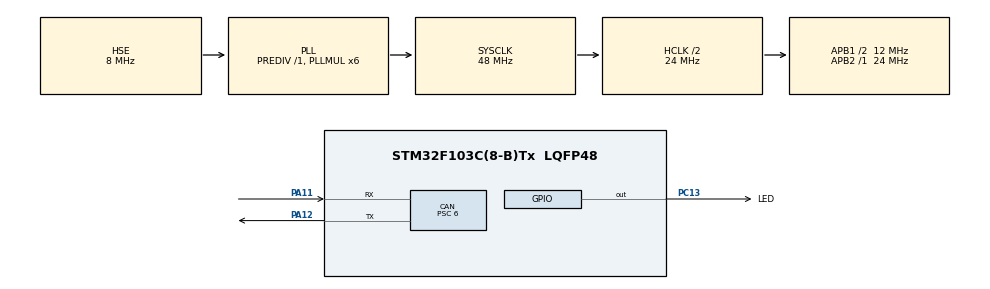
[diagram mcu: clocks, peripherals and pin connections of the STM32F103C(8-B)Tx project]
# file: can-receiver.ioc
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CAN.BS1=CAN_BS1_5TQ
CAN.BS2=CAN_BS2_2TQ
CAN.CalculateTimeBit=4000
CAN.CalculateTimeQuantum=500.0
CAN.NART=DISABLE
CAN.Prescaler=6
Mcu.Family=STM32F1
Mcu.Name=STM32F103C(8-B)Tx
Mcu.Package=LQFP48
NVIC.PriorityGroup=NVIC_PRIORITYGROUP_4
NVIC.USB_LP_CAN1_RX0_IRQn=true\:0\:0\:false\:true\:true\:1\:true\:true
PA11.Mode=Master
PA11.Signal=CAN_RX
PA12.Mode=Master
PA12.Signal=CAN_TX
PA13.Mode=Serial_Wire
PA13.Signal=SYS_JTMS-SWDIO
PA14.Mode=Serial_Wire
PA14.Signal=SYS_JTCK-SWCLK
PC13-TAMPER-RTC.GPIO_Label=LED
PC13-TAMPER-RTC.Signal=GPIO_Output
PD0-OSC_IN.Mode=HSE-External-Oscillator
PD0-OSC_IN.Signal=RCC_OSC_IN
PD1-OSC_OUT.Mode=HSE-External-Oscillator
PD1-OSC_OUT.Signal=RCC_OSC_OUT
ProjectManager.HeapSize=0x200
ProjectManager.StackSize=0x400
ProjectManager.TargetToolchain=STM32CubeIDE
RCC.AHBCLKDivider=RCC_SYSCLK_DIV2
RCC.AHBFreq_Value=24000000
RCC.APB1CLKDivider=RCC_HCLK_DIV2
RCC.APB1Freq_Value=12000000
RCC.APB1TimFreq_Value=24000000
RCC.APB2Freq_Value=24000000
RCC.APB2TimFreq_Value=24000000
RCC.HCLKFreq_Value=24000000
RCC.PLLMUL=RCC_PLL_MUL6
RCC.PLLSourceVirtual=RCC_PLLSOURCE_HSE
RCC.SYSCLKFreq_VALUE=48000000
RCC.SYSCLKSource=RCC_SYSCLKSOURCE_PLLCLK
RCC.USBFreq_Value=48000000
board=custom

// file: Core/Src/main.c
/* USER CODE BEGIN Header */
/**
 ******************************************************************************
 * @file           : main.c
 * @brief          : Main program body
 ******************************************************************************
 * @attention
 *
 * <h2><center>&copy; Copyright (c) 2020 STMicroelectronics.
 * All rights reserved.</center></h2>
 *
 * This software component is licensed by ST under BSD 3-Clause license,
 * the "License"; You may not use this file except in compliance with the
 * License. You may obtain a copy of the License at:
 *                        opensource.org/licenses/BSD-3-Clause
 *
 ******************************************************************************
 */
/* USER CODE END Header */

#include "main.h"

CAN_HandleTypeDef hcan;

/* USER CODE BEGIN PV */
CAN_TxHeaderTypeDef pHeader;
uint32_t pTxMailbox;
/* USER CODE END PV */

void SystemClock_Config(void);
static void MX_GPIO_Init(void);
static void MX_CAN_Init(void);
static void MX_NVIC_Init(void);

int main(void) {

	/* MCU Configuration--------------------------------------------------------*/

	/* Reset of all peripherals, Initializes the Flash interface and the Systick. */
	HAL_Init();

	/* Configure the system clock */
	SystemClock_Config();

	/* Initialize all configured peripherals */
	MX_GPIO_Init();
	MX_CAN_Init();

	/* Initialize interrupts */
	MX_NVIC_Init();
	/* USER CODE BEGIN 2 */
	uint8_t statusHAL;
	/* USER CODE END 2 */

	/* Infinite loop */
	while (1) {

	}
}

void SystemClock_Config(void) {
	RCC_OscInitTypeDef RCC_OscInitStruct = { 0 };
	RCC_ClkInitTypeDef RCC_ClkInitStruct = { 0 };

	/** Initializes the CPU, AHB and APB busses clocks
	 */
	RCC_OscInitStruct.OscillatorType = RCC_OSCILLATORTYPE_HSE;
	RCC_OscInitStruct.HSEState = RCC_HSE_ON;
	RCC_OscInitStruct.HSEPredivValue = RCC_HSE_PREDIV_DIV1;
	RCC_OscInitStruct.HSIState = RCC_HSI_ON;
	RCC_OscInitStruct.PLL.PLLState = RCC_PLL_ON;
	RCC_OscInitStruct.PLL.PLLSource = RCC_PLLSOURCE_HSE;
	RCC_OscInitStruct.PLL.PLLMUL = RCC_PLL_MUL6;
	if (HAL_RCC_OscConfig(&RCC_OscInitStruct) != HAL_OK) {
		Error_Handler();
	}
	/** Initializes the CPU, AHB and APB busses clocks
	 */
	RCC_ClkInitStruct.ClockType = RCC_CLOCKTYPE_HCLK | RCC_CLOCKTYPE_SYSCLK
			| RCC_CLOCKTYPE_PCLK1 | RCC_CLOCKTYPE_PCLK2;
	RCC_ClkInitStruct.SYSCLKSource = RCC_SYSCLKSOURCE_PLLCLK;
	RCC_ClkInitStruct.AHBCLKDivider = RCC_SYSCLK_DIV2;
	RCC_ClkInitStruct.APB1CLKDivider = RCC_HCLK_DIV2;
	RCC_ClkInitStruct.APB2CLKDivider = RCC_HCLK_DIV1;

	if (HAL_RCC_ClockConfig(&RCC_ClkInitStruct, FLASH_LATENCY_1) != HAL_OK) {
		Error_Handler();
	}
}

/**
 * @brief NVIC Configuration.
 * @retval None
 */
static void MX_NVIC_Init(void) {
	/* USB_LP_CAN1_RX0_IRQn interrupt configuration */
	HAL_NVIC_SetPriority(USB_LP_CAN1_RX0_IRQn, 0, 0);
	HAL_NVIC_EnableIRQ(USB_LP_CAN1_RX0_IRQn);
}

static void MX_CAN_Init(void) {

	hcan.Instance = CAN1;
	hcan.Init.Prescaler = 6;
	hcan.Init.Mode = CAN_MODE_NORMAL;
	hcan.Init.SyncJumpWidth = CAN_SJW_1TQ;
	hcan.Init.TimeSeg1 = CAN_BS1_5TQ;
	hcan.Init.TimeSeg2 = CAN_BS2_2TQ;
	hcan.Init.TimeTriggeredMode = DISABLE;
	hcan.Init.AutoBusOff = DISABLE;
	hcan.Init.AutoWakeUp = DISABLE;
	hcan.Init.AutoRetransmission = DISABLE;
	hcan.Init.ReceiveFifoLocked = DISABLE;
	hcan.Init.TransmitFifoPriority = DISABLE;
	if (HAL_CAN_Init(&hcan) != HAL_OK) {
		Error_Handler();
	}
	/* USER CODE BEGIN CAN_Init 2 */
	uint8_t statusHAL;

	CAN_FilterTypeDef sFilterConfig;

	sFilterConfig.FilterMode = CAN_FILTERMODE_IDMASK;
	sFilterConfig.FilterScale = CAN_FILTERSCALE_32BIT;
	sFilterConfig.FilterIdHigh = 0x0000;
	sFilterConfig.FilterIdLow = 0x0000;
	sFilterConfig.FilterMaskIdHigh = 0x0000;
	sFilterConfig.FilterMaskIdLow = 0x0000;
	sFilterConfig.FilterFIFOAssignment = CAN_FILTER_FIFO0;
	sFilterConfig.FilterActivation = ENABLE;
	sFilterConfig.FilterBank = 0;

	statusHAL = HAL_CAN_ConfigFilter(&hcan, &sFilterConfig);
	if (statusHAL != HAL_OK) {
		Error_Handler();
	}

	statusHAL = HAL_CAN_ActivateNotification(&hcan,
			CAN_IT_RX_FIFO0_MSG_PENDING);
	if (statusHAL != HAL_OK) {
		Error_Handler();
	}

	statusHAL = HAL_CAN_Start(&hcan);
	if (statusHAL != HAL_OK) {
		Error_Handler();
	}
	/* USER CODE END CAN_Init 2 */

}

static void MX_GPIO_Init(void) {
	GPIO_InitTypeDef GPIO_InitStruct = { 0 };

	/* GPIO Ports Clock Enable */
	__HAL_RCC_GPIOC_CLK_ENABLE();
	__HAL_RCC_GPIOD_CLK_ENABLE();
	__HAL_RCC_GPIOA_CLK_ENABLE();

	/*Configure GPIO pin Output Level */
	HAL_GPIO_WritePin(LED_GPIO_Port, LED_Pin, GPIO_PIN_RESET);

	/*Configure GPIO pin : LED_Pin */
	GPIO_InitStruct.Pin = LED_Pin;
	GPIO_InitStruct.Mode = GPIO_MODE_OUTPUT_PP;
	GPIO_InitStruct.Pull = GPIO_NOPULL;
	GPIO_InitStruct.Speed = GPIO_SPEED_FREQ_LOW;
	HAL_GPIO_Init(LED_GPIO_Port, &GPIO_InitStruct);

}

/* USER CODE BEGIN 4 */
void HAL_CAN_RxFifo0MsgPendingCallback(CAN_HandleTypeDef *hcan) {
	uint8_t aData[8];

	HAL_CAN_GetRxMessage(&hcan, &pTxMailbox, &pHeader, aData);

	HAL_GPIO_TogglePin(GPIOC, LED_Pin);

	return;
}
/* USER CODE END 4 */

void Error_Handler(void) {
	/* USER CODE BEGIN Error_Handler_Debug */
	/* User can add his own implementation to report the HAL error return state */
	for (;;)
		;
	/* USER CODE END Error_Handler_Debug */
}

/************************ (C) COPYRIGHT STMicroelectronics *****END OF FILE****/
